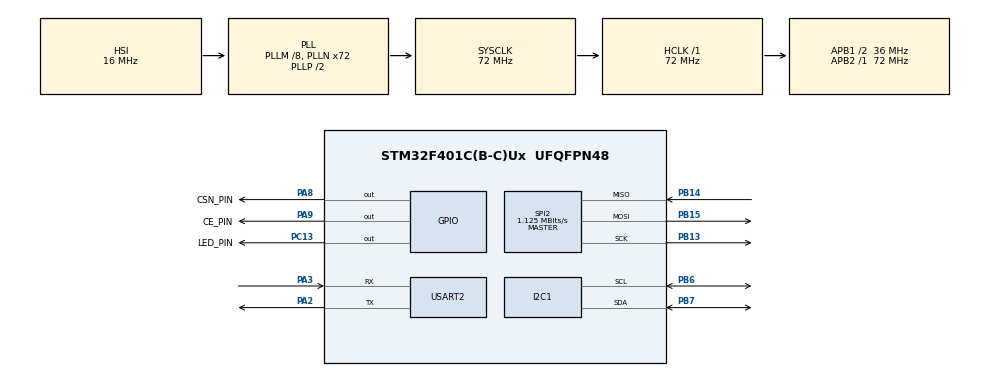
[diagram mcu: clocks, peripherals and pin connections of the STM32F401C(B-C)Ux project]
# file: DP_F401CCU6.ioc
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Mcu.Family=STM32F4
Mcu.Name=STM32F401C(B-C)Ux
Mcu.Package=UFQFPN48
NVIC.PriorityGroup=NVIC_PRIORITYGROUP_4
PA13.Mode=Serial_Wire
PA13.Signal=SYS_JTMS-SWDIO
PA14.Mode=Serial_Wire
PA14.Signal=SYS_JTCK-SWCLK
PA2.Mode=Asynchronous
PA2.Signal=USART2_TX
PA3.Mode=Asynchronous
PA3.Signal=USART2_RX
PA8.GPIO_Label=CSN_PIN
PA8.Signal=GPIO_Output
PA9.GPIO_Label=CE_PIN
PA9.Signal=GPIO_Output
PB13.Mode=Full_Duplex_Master
PB13.Signal=SPI2_SCK
PB14.Mode=Full_Duplex_Master
PB14.Signal=SPI2_MISO
PB15.Mode=Full_Duplex_Master
PB15.Signal=SPI2_MOSI
PB6.Mode=I2C
PB6.Signal=I2C1_SCL
PB7.Mode=I2C
PB7.Signal=I2C1_SDA
PC13-ANTI_TAMP.GPIO_Label=LED_PIN
PC13-ANTI_TAMP.Signal=GPIO_Output
PH0\ -\ OSC_IN.Mode=HSE-External-Oscillator
PH0\ -\ OSC_IN.Signal=RCC_OSC_IN
PH1\ -\ OSC_OUT.Mode=HSE-External-Oscillator
PH1\ -\ OSC_OUT.Signal=RCC_OSC_OUT
ProjectManager.HeapSize=0x200
ProjectManager.StackSize=0x400
ProjectManager.TargetToolchain=STM32CubeIDE
RCC.48MHZClocksFreq_Value=36000000
RCC.AHBFreq_Value=72000000
RCC.APB1CLKDivider=RCC_HCLK_DIV2
RCC.APB1Freq_Value=36000000
RCC.APB1TimFreq_Value=72000000
RCC.APB2Freq_Value=72000000
RCC.APB2TimFreq_Value=72000000
RCC.CortexFreq_Value=72000000
RCC.HCLKFreq_Value=72000000
RCC.HSE_VALUE=25000000
RCC.HSI_VALUE=16000000
RCC.LSE_VALUE=32768
RCC.PLLM=8
RCC.PLLN=72
RCC.SYSCLKFreq_VALUE=72000000
RCC.SYSCLKSource=RCC_SYSCLKSOURCE_PLLCLK
RCC.VCOOutputFreq_Value=144000000
SPI2.BaudRatePrescaler=SPI_BAUDRATEPRESCALER_32
SPI2.CalculateBaudRate=1.125 MBits/s
SPI2.Direction=SPI_DIRECTION_2LINES
SPI2.Mode=SPI_MODE_MASTER
SPI2.VirtualType=VM_MASTER
USART2.VirtualMode=VM_ASYNC
board=custom

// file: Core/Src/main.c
/* USER CODE BEGIN Header */
/**
 ******************************************************************************
 * @file           : main.c
 * @brief          : Main program body
 ******************************************************************************
 * @attention
 *
 * Copyright (c) 2023 STMicroelectronics.
 * All rights reserved.
 *
 * This software is licensed under terms that can be found in the LICENSE file
 * in the root directory of this software component.
 * If no LICENSE file comes with this software, it is provided AS-IS.
 *
 ******************************************************************************
 */
/* USER CODE END Header */
#include "main.h"

/* USER CODE BEGIN Includes */
#include "nrf_helper.h"
#include "utilities.h"
#include "ADP8XX_DP_SENSOR.h"
/* USER CODE END Includes */

I2C_HandleTypeDef hi2c1;

SPI_HandleTypeDef hspi2;

UART_HandleTypeDef huart2;

void SystemClock_Config(void);
static void MX_GPIO_Init(void);
static void MX_SPI2_Init(void);
static void MX_USART2_UART_Init(void);
static void MX_I2C1_Init(void);

int main(void) {

	/* MCU Configuration--------------------------------------------------------*/

	/* Reset of all peripherals, Initializes the Flash interface and the Systick. */
	HAL_Init();

	/* Configure the system clock */
	SystemClock_Config();

	/* Initialize all configured peripherals */
	MX_GPIO_Init();
	MX_SPI2_Init();
	MX_USART2_UART_Init();
	MX_I2C1_Init();
	/* USER CODE BEGIN 2 */
	HAL_StatusTypeDef ret = dp_sens_init();
	if (ret != HAL_OK) {
		Error_Handler();
	}
	nrf_init();
	Switch_to_Transmitt_mode();
	/* USER CODE END 2 */

	/* Infinite loop */
	while (1) {

		/* USER CODE BEGIN 3 */
		send_DP_sensor_value_to_gateway();
//		HANDLE_RECEIVED_MESSAGE_FROM_GATEWAY();
		HAL_GPIO_TogglePin(LED_PIN_GPIO_Port, LED_PIN_Pin);
		HAL_Delay(4000);
		//MEASURE DP SENSOR DATA

	}
	/* USER CODE END 3 */
}

void SystemClock_Config(void) {
	RCC_OscInitTypeDef RCC_OscInitStruct = { 0 };
	RCC_ClkInitTypeDef RCC_ClkInitStruct = { 0 };

	/** Configure the main internal regulator output voltage
	 */
	__HAL_RCC_PWR_CLK_ENABLE();
	__HAL_PWR_VOLTAGESCALING_CONFIG(PWR_REGULATOR_VOLTAGE_SCALE2);

	/** Initializes the RCC Oscillators according to the specified parameters
	 * in the RCC_OscInitTypeDef structure.
	 */
	RCC_OscInitStruct.OscillatorType = RCC_OSCILLATORTYPE_HSI;
	RCC_OscInitStruct.HSIState = RCC_HSI_ON;
	RCC_OscInitStruct.HSICalibrationValue = RCC_HSICALIBRATION_DEFAULT;
	RCC_OscInitStruct.PLL.PLLState = RCC_PLL_ON;
	RCC_OscInitStruct.PLL.PLLSource = RCC_PLLSOURCE_HSI;
	RCC_OscInitStruct.PLL.PLLM = 8;
	RCC_OscInitStruct.PLL.PLLN = 72;
	RCC_OscInitStruct.PLL.PLLP = RCC_PLLP_DIV2;
	RCC_OscInitStruct.PLL.PLLQ = 4;
	if (HAL_RCC_OscConfig(&RCC_OscInitStruct) != HAL_OK) {
		Error_Handler();
	}

	/** Initializes the CPU, AHB and APB buses clocks
	 */
	RCC_ClkInitStruct.ClockType = RCC_CLOCKTYPE_HCLK | RCC_CLOCKTYPE_SYSCLK
			| RCC_CLOCKTYPE_PCLK1 | RCC_CLOCKTYPE_PCLK2;
	RCC_ClkInitStruct.SYSCLKSource = RCC_SYSCLKSOURCE_PLLCLK;
	RCC_ClkInitStruct.AHBCLKDivider = RCC_SYSCLK_DIV1;
	RCC_ClkInitStruct.APB1CLKDivider = RCC_HCLK_DIV2;
	RCC_ClkInitStruct.APB2CLKDivider = RCC_HCLK_DIV1;

	if (HAL_RCC_ClockConfig(&RCC_ClkInitStruct, FLASH_LATENCY_2) != HAL_OK) {
		Error_Handler();
	}
}

static void MX_I2C1_Init(void) {

	hi2c1.Instance = I2C1;
	hi2c1.Init.ClockSpeed = 100000;
	hi2c1.Init.DutyCycle = I2C_DUTYCYCLE_2;
	hi2c1.Init.OwnAddress1 = 0;
	hi2c1.Init.AddressingMode = I2C_ADDRESSINGMODE_7BIT;
	hi2c1.Init.DualAddressMode = I2C_DUALADDRESS_DISABLE;
	hi2c1.Init.OwnAddress2 = 0;
	hi2c1.Init.GeneralCallMode = I2C_GENERALCALL_DISABLE;
	hi2c1.Init.NoStretchMode = I2C_NOSTRETCH_DISABLE;
	if (HAL_I2C_Init(&hi2c1) != HAL_OK) {
		Error_Handler();
	}

}

static void MX_SPI2_Init(void) {

	/* SPI2 parameter configuration*/
	hspi2.Instance = SPI2;
	hspi2.Init.Mode = SPI_MODE_MASTER;
	hspi2.Init.Direction = SPI_DIRECTION_2LINES;
	hspi2.Init.DataSize = SPI_DATASIZE_8BIT;
	hspi2.Init.CLKPolarity = SPI_POLARITY_LOW;
	hspi2.Init.CLKPhase = SPI_PHASE_1EDGE;
	hspi2.Init.NSS = SPI_NSS_SOFT;
	hspi2.Init.BaudRatePrescaler = SPI_BAUDRATEPRESCALER_32;
	hspi2.Init.FirstBit = SPI_FIRSTBIT_MSB;
	hspi2.Init.TIMode = SPI_TIMODE_DISABLE;
	hspi2.Init.CRCCalculation = SPI_CRCCALCULATION_DISABLE;
	hspi2.Init.CRCPolynomial = 10;
	if (HAL_SPI_Init(&hspi2) != HAL_OK) {
		Error_Handler();
	}

}

static void MX_USART2_UART_Init(void) {

	huart2.Instance = USART2;
	huart2.Init.BaudRate = 115200;
	huart2.Init.WordLength = UART_WORDLENGTH_8B;
	huart2.Init.StopBits = UART_STOPBITS_1;
	huart2.Init.Parity = UART_PARITY_NONE;
	huart2.Init.Mode = UART_MODE_TX_RX;
	huart2.Init.HwFlowCtl = UART_HWCONTROL_NONE;
	huart2.Init.OverSampling = UART_OVERSAMPLING_16;
	if (HAL_UART_Init(&huart2) != HAL_OK) {
		Error_Handler();
	}

}

static void MX_GPIO_Init(void) {
	GPIO_InitTypeDef GPIO_InitStruct = { 0 };

	/* GPIO Ports Clock Enable */
	__HAL_RCC_GPIOC_CLK_ENABLE();
	__HAL_RCC_GPIOH_CLK_ENABLE();
	__HAL_RCC_GPIOA_CLK_ENABLE();
	__HAL_RCC_GPIOB_CLK_ENABLE();

	/*Configure GPIO pin Output Level */
	HAL_GPIO_WritePin(LED_PIN_GPIO_Port, LED_PIN_Pin, GPIO_PIN_RESET);

	/*Configure GPIO pin Output Level */
	HAL_GPIO_WritePin(GPIOA, CSN_PIN_Pin | CE_PIN_Pin, GPIO_PIN_RESET);

	/*Configure GPIO pin : LED_PIN_Pin */
	GPIO_InitStruct.Pin = LED_PIN_Pin;
	GPIO_InitStruct.Mode = GPIO_MODE_OUTPUT_PP;
	GPIO_InitStruct.Pull = GPIO_NOPULL;
	GPIO_InitStruct.Speed = GPIO_SPEED_FREQ_LOW;
	HAL_GPIO_Init(LED_PIN_GPIO_Port, &GPIO_InitStruct);

	/*Configure GPIO pins : CSN_PIN_Pin CE_PIN_Pin */
	GPIO_InitStruct.Pin = CSN_PIN_Pin | CE_PIN_Pin;
	GPIO_InitStruct.Mode = GPIO_MODE_OUTPUT_PP;
	GPIO_InitStruct.Pull = GPIO_NOPULL;
	GPIO_InitStruct.Speed = GPIO_SPEED_FREQ_LOW;
	HAL_GPIO_Init(GPIOA, &GPIO_InitStruct);

}

void Error_Handler(void) {
	/* USER CODE BEGIN Error_Handler_Debug */
	/* User can add his own implementation to report the HAL error return state */
	__disable_irq();
	while (1) {
		HAL_GPIO_TogglePin(LED_PIN_GPIO_Port, LED_PIN_Pin);
		HAL_Delay(50);
	}
	/* USER CODE END Error_Handler_Debug */
}
